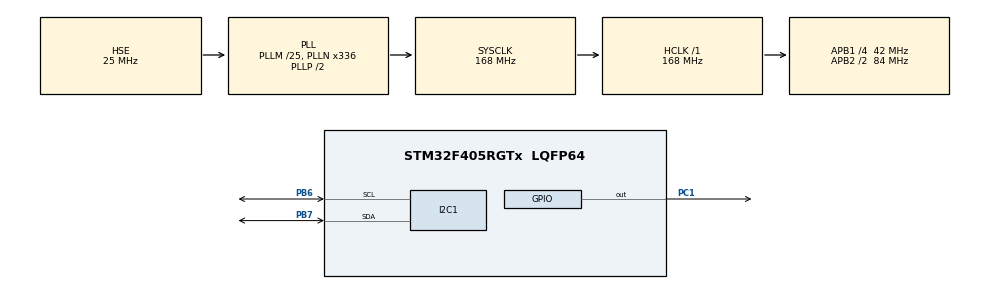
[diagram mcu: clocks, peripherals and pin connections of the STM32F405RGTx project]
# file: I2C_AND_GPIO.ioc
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Mcu.Family=STM32F4
Mcu.Name=STM32F405RGTx
Mcu.Package=LQFP64
NVIC.PriorityGroup=NVIC_PRIORITYGROUP_4
PB6.Mode=I2C
PB6.Signal=I2C1_SCL
PB7.Mode=I2C
PB7.Signal=I2C1_SDA
PC1.Signal=GPIO_Output
PC14-OSC32_IN.Mode=LSE-External-Oscillator
PC14-OSC32_IN.Signal=RCC_OSC32_IN
PC15-OSC32_OUT.Mode=LSE-External-Oscillator
PC15-OSC32_OUT.Signal=RCC_OSC32_OUT
PH0-OSC_IN.Mode=HSE-External-Oscillator
PH0-OSC_IN.Signal=RCC_OSC_IN
PH1-OSC_OUT.Mode=HSE-External-Oscillator
PH1-OSC_OUT.Signal=RCC_OSC_OUT
ProjectManager.HeapSize=0x200
ProjectManager.StackSize=0x400
ProjectManager.TargetToolchain=STM32CubeIDE
RCC.48MHZClocksFreq_Value=48000000
RCC.AHBFreq_Value=168000000
RCC.APB1CLKDivider=RCC_HCLK_DIV4
RCC.APB1Freq_Value=42000000
RCC.APB1TimFreq_Value=84000000
RCC.APB2CLKDivider=RCC_HCLK_DIV2
RCC.APB2Freq_Value=84000000
RCC.APB2TimFreq_Value=168000000
RCC.CortexFreq_Value=168000000
RCC.HCLKFreq_Value=168000000
RCC.HSE_VALUE=25000000
RCC.HSI_VALUE=16000000
RCC.PLLM=25
RCC.PLLN=336
RCC.PLLQ=7
RCC.PLLSourceVirtual=RCC_PLLSOURCE_HSE
RCC.SYSCLKFreq_VALUE=168000000
RCC.SYSCLKSource=RCC_SYSCLKSOURCE_PLLCLK
RCC.VCOOutputFreq_Value=336000000
board=custom

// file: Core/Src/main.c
/* USER CODE BEGIN Header */
/**
  ******************************************************************************
  * @file           : main.c
  * @brief          : Main program body
  ******************************************************************************
  * @attention
  *
  * <h2><center>&copy; Copyright (c) 2020 STMicroelectronics.
  * All rights reserved.</center></h2>
  *
  * This software component is licensed by ST under BSD 3-Clause license,
  * the "License"; You may not use this file except in compliance with the
  * License. You may obtain a copy of the License at:
  *                        opensource.org/licenses/BSD-3-Clause
  *
  ******************************************************************************
  */
/* USER CODE END Header */

#include "main.h"
#include "i2c.h"
#include "gpio.h"

/* USER CODE BEGIN PD */
#define LSM6DS33_DEV_ADD	0x6A
#define I2C_MEMADD_SIZE_8BIT	0x00000001U
#define LINEAR_ACCEL_RANGE 2
#define GYRO_RANGE 2000
/* USER CODE END PD */

/* USER CODE BEGIN PV */
unsigned char LSMwrite[6];
unsigned char temperatureData[2];
unsigned char linearAccelData[6];
unsigned char angularRateData[6];

HAL_StatusTypeDef i2cStats;
float temperature;
float linearAccel[3];
float angularRate[3];

/* USER CODE END PV */

void SystemClock_Config(void);
/* USER CODE BEGIN PFP */
float calcLinearAccel(int16_t, int);
float calcGyro(int16_t twosCompAdjustedInput, int gyroRange);
int16_t twosComp2ByteToSignedInt(unsigned char *);
/* USER CODE END PFP */

int main(void)
{

  /* MCU Configuration--------------------------------------------------------*/

  /* Reset of all peripherals, Initializes the Flash interface and the Systick. */
  HAL_Init();

  /* Configure the system clock */
  SystemClock_Config();

  /* Initialize all configured peripherals */
  MX_GPIO_Init();
  MX_I2C1_Init();
  /* USER CODE BEGIN 2 */
  HAL_I2C_StateTypeDef state;
  /* USER CODE END 2 */

  /* Infinite loop */
  /* USER CODE BEGIN WHILE */

  LSMwrite[0] = 0b01010000; //CTRL1_XL 2g, 400Hz, normal mode
  i2cStats = HAL_I2C_Mem_Write(&hi2c1, LSM6DS33_DEV_ADD << 1, 0x10, I2C_MEMADD_SIZE_8BIT, LSMwrite, 1, 100); // reset FUNC_CFG_ACCESS
  HAL_Delay(20);

  LSMwrite[0] = 0b01011100; //CTRL2_XL 2000dps, gyro full scale off, normal mode
  i2cStats = HAL_I2C_Mem_Write(&hi2c1, LSM6DS33_DEV_ADD << 1, 0x11, I2C_MEMADD_SIZE_8BIT, LSMwrite, 1, 100); // reset FUNC_CFG_ACCESS
  HAL_Delay(20);

  while (1)
  {
    /* USER CODE END WHILE */

    /* USER CODE BEGIN 3 */
	HAL_GPIO_WritePin(GPIOC, GPIO_PIN_1, GPIO_PIN_SET);
	HAL_Delay(200);
	HAL_GPIO_WritePin(GPIOC, GPIO_PIN_1, GPIO_PIN_RESET);
	HAL_Delay(200);
	CDC_Transmit_FS(buff, sizeof(buff));

	state=HAL_I2C_GetState(&hi2c1);
	if(state==HAL_I2C_STATE_READY||state==HAL_I2C_STATE_BUSY_RX){
		//Read from temperature register
		i2cStats = HAL_I2C_Mem_Read(&hi2c1, LSM6DS33_DEV_ADD << 1, 0x20, I2C_MEMADD_SIZE_8BIT, temperatureData, 2, 100); //reading two byte from temperature register
		temperature = twosComp2ByteToSignedInt(temperatureData);
		temperature = temperature / 16.0 + 25.0;
		HAL_Delay(20); //just to be safe

		//Read from Acceleration register
		i2cStats = HAL_I2C_Mem_Read(&hi2c1, LSM6DS33_DEV_ADD << 1, 0x28, I2C_MEMADD_SIZE_8BIT, linearAccelData, 6, 100); //reading from x accel LSB
		linearAccel[0] = calcLinearAccel(twosComp2ByteToSignedInt(linearAccelData), LINEAR_ACCEL_RANGE);
		linearAccel[1] = calcLinearAccel(twosComp2ByteToSignedInt(&linearAccelData[2]), LINEAR_ACCEL_RANGE);
		linearAccel[2] = calcLinearAccel(twosComp2ByteToSignedInt(&linearAccelData[4]), LINEAR_ACCEL_RANGE);
		HAL_Delay(20); //just to be safe

		i2cStats = HAL_I2C_Mem_Read(&hi2c1, LSM6DS33_DEV_ADD << 1, 0x22, I2C_MEMADD_SIZE_8BIT, angularRateData, 6, 100); //reading from x accel LSB
		angularRate[0] = calcGyro(twosComp2ByteToSignedInt(angularRateData), GYRO_RANGE);
		angularRate[1] = calcGyro(twosComp2ByteToSignedInt(&angularRateData[2]), GYRO_RANGE);
		angularRate[2] = calcGyro(twosComp2ByteToSignedInt(&angularRateData[4]), GYRO_RANGE);
	}

  }
  /* USER CODE END 3 */
}

void SystemClock_Config(void)
{
  RCC_OscInitTypeDef RCC_OscInitStruct = {0};
  RCC_ClkInitTypeDef RCC_ClkInitStruct = {0};

  /** Configure the main internal regulator output voltage
  */
  __HAL_RCC_PWR_CLK_ENABLE();
  __HAL_PWR_VOLTAGESCALING_CONFIG(PWR_REGULATOR_VOLTAGE_SCALE1);
  /** Initializes the CPU, AHB and APB busses clocks
  */
  RCC_OscInitStruct.OscillatorType = RCC_OSCILLATORTYPE_HSE;
  RCC_OscInitStruct.HSEState = RCC_HSE_ON;
  RCC_OscInitStruct.PLL.PLLState = RCC_PLL_ON;
  RCC_OscInitStruct.PLL.PLLSource = RCC_PLLSOURCE_HSE;
  RCC_OscInitStruct.PLL.PLLM = 25;
  RCC_OscInitStruct.PLL.PLLN = 336;
  RCC_OscInitStruct.PLL.PLLP = RCC_PLLP_DIV2;
  RCC_OscInitStruct.PLL.PLLQ = 7;
  if (HAL_RCC_OscConfig(&RCC_OscInitStruct) != HAL_OK)
  {
    Error_Handler();
  }
  /** Initializes the CPU, AHB and APB busses clocks
  */
  RCC_ClkInitStruct.ClockType = RCC_CLOCKTYPE_HCLK|RCC_CLOCKTYPE_SYSCLK
                              |RCC_CLOCKTYPE_PCLK1|RCC_CLOCKTYPE_PCLK2;
  RCC_ClkInitStruct.SYSCLKSource = RCC_SYSCLKSOURCE_PLLCLK;
  RCC_ClkInitStruct.AHBCLKDivider = RCC_SYSCLK_DIV1;
  RCC_ClkInitStruct.APB1CLKDivider = RCC_HCLK_DIV4;
  RCC_ClkInitStruct.APB2CLKDivider = RCC_HCLK_DIV2;

  if (HAL_RCC_ClockConfig(&RCC_ClkInitStruct, FLASH_LATENCY_5) != HAL_OK)
  {
    Error_Handler();
  }
}

/* USER CODE BEGIN 4 */
float calcLinearAccel(int16_t twosCompAdjustedInput, int accelConvertionRatio){
	return (float)twosCompAdjustedInput * 0.061 * (accelConvertionRatio >> 1) / 1000;
}

float calcGyro(int16_t twosCompAdjustedInput, int gyroRange){
	uint8_t gyroRangeDivisor = gyroRange / 125;
	if ( gyroRange == 245 ) {
		gyroRangeDivisor = 2;
	}

	float output = (float)twosCompAdjustedInput * 4.375 * (gyroRangeDivisor) / 1000;
	return output;
}

//Expect two byte char array
int16_t twosComp2ByteToSignedInt(unsigned char * input){
	if (input == NULL) return -1;
	return (int16_t) ((signed char) input[1] << 8) | input[0];
}

/* USER CODE END 4 */

void Error_Handler(void)
{
}

/************************ (C) COPYRIGHT STMicroelectronics *****END OF FILE****/
